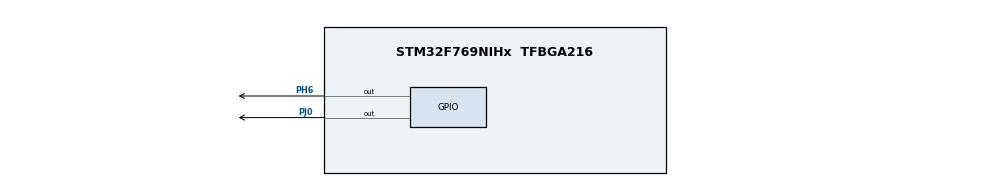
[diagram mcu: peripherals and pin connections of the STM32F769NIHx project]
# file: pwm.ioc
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Mcu.Family=STM32F7
Mcu.Name=STM32F769NIHx
Mcu.Package=TFBGA216
NVIC.PriorityGroup=NVIC_PRIORITYGROUP_4
PH6.Signal=GPIO_Output
PJ0.Signal=GPIO_Output
ProjectManager.HeapSize=0x200
ProjectManager.StackSize=0x400
ProjectManager.TargetToolchain=STM32CubeIDE
RCC.HSE_VALUE=25000000
RCC.HSI_VALUE=16000000
RCC.LSE_VALUE=32768
RCC.USBFreq_Value=96000000
RCC.VCOOutputFreq_Value=192000000
TIM3.Period=499
TIM3.Prescaler=48000
VP_TIM3_VS_ClockSourceINT.Mode=Internal
board=custom

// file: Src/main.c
/* USER CODE BEGIN Header */
/**
  ******************************************************************************
  * @file           : main.c
  * @brief          : Main program body
  ******************************************************************************
  * @attention
  *
  * <h2><center>&copy; Copyright (c) 2019 STMicroelectronics.
  * All rights reserved.</center></h2>
  *
  * This software component is licensed by ST under BSD 3-Clause license,
  * the "License"; You may not use this file except in compliance with the
  * License. You may obtain a copy of the License at:
  *                        opensource.org/licenses/BSD-3-Clause
  *
  ******************************************************************************
  */
/* USER CODE END Header */

#include "main.h"

TIM_HandleTypeDef htim3;

void SystemClock_Config(void);
static void MX_GPIO_Init(void);
static void MX_TIM3_Init(void);

/* USER CODE BEGIN 0 */

/*void HAL_TIM_PeriodElapsedCallback(TIM_HandleTypeDef *htim){
	if(htim->Instance==TIM3){
		HAL_GPIO_TogglePin(GPIOH,GPIO_PIN_6);
	}
}*/

void TIM3_IRQHandler(void){
	/*if(TIM3->SR & TIM_SR_UIF){ //2000
	  TIM3->SR &= ~TIM_SR_UIF;
	  HAL_GPIO_WritePin(GPIOJ,GPIO_PIN_0,GPIO_PIN_RESET);
	}
	else if(TIM3->SR & TIM_SR_CC3OF){ //1000
		TIM3->SR &= ~TIM_SR_CC3OF;
		HAL_GPIO_WritePin(GPIOJ,GPIO_PIN_0,GPIO_PIN_SET);
	}*/
	if(TIM3->SR & TIM_SR_UIF) // if UIF flag is set
	  {
	  TIM3->SR &= ~TIM_SR_UIF;  // clear UIF flag
	  TIM3->CCR3 += 5;	         // increase ch3 duty
	  if(TIM3->CCR3 == 100)	{    // if maximum
	    TIM3->CCR3 = 0;	        // set to zero
	    HAL_GPIO_WritePin(GPIOJ,GPIO_PIN_0,GPIO_PIN_RESET);
	  }
	  TIM3->CCR4 -= 5;	         // decrease ch4 duty
	  if(TIM3->CCR4 == 0)	      // if minimum
	  {
	    TIM3->CCR4 = 250;	      // set to maximum
	    HAL_GPIO_WritePin(GPIOJ,GPIO_PIN_0,GPIO_PIN_SET);
	  }
	}
}

/* USER CODE END 0 */

int main(void)
{

  /* MCU Configuration--------------------------------------------------------*/

  /* Reset of all peripherals, Initializes the Flash interface and the Systick. */
  HAL_Init();

  /* Configure the system clock */
  SystemClock_Config();

  /* Initialize all configured peripherals */
  MX_GPIO_Init();
  MX_TIM3_Init();
  /* USER CODE BEGIN 2 */
  //HAL_TIM_Base_Start_IT(&htim3);
/* RCC->APB1ENR |= RCC_APB1ENR_TIM3EN;
  TIM3->PSC  = 15999;
  TIM3->ARR = 2000;
  TIM3->CCER = 256;
  TIM3->CR1  = TIM_CR1_CEN;
  TIM3->CCMR2 = TIM_CCMR2_OC3M_2 | TIM_CCMR2_OC3M_1; // PWM mode on channel 3

  TIM3->CCR3 = 1000;

  TIM3->DIER = TIM_DIER_UIE | TIM_DIER_CC3IE; // Enable update interrupt (timer level)
  NVIC_EnableIRQ(TIM3_IRQn); // Enable interrupt from TIM3 (NVIC level)
  */
  TIM3->PSC = 0;	// Set prescaler to 24 000 (PSC + 1)
  TIM3->ARR = 250;	// Auto reload value 500

  TIM3->CCR3 = 0;	  // Start PWM duty for channel 3
  TIM3->CCR4 = 500; // Start PWM duty for channel 4

  TIM3->CCMR2 = TIM_CCMR2_OC4M_2 | TIM_CCMR2_OC4M_1 |
                TIM_CCMR2_OC3M_2 | TIM_CCMR2_OC3M_1; // PWM mode on channel 3 & 4

  TIM3->CCER = TIM_CCER_CC4E | TIM_CCER_CC3E; // Enable compare on channel 3 & 4
  TIM3->CR1  = TIM_CR1_CEN;	// Enable timer

  TIM3->DIER = TIM_DIER_UIE; // Enable update interrupt (timer level)
  NVIC_EnableIRQ(TIM3_IRQn); // Enable interrupt from TIM3 (NVIC level)

  /* USER CODE END 2 */

  /* Infinite loop */
  while (1)
  {
	  HAL_GPIO_WritePin(GPIOH,GPIO_PIN_6,GPIO_PIN_SET);
	  HAL_Delay(1000);
	  HAL_GPIO_WritePin(GPIOH,GPIO_PIN_6,GPIO_PIN_RESET);
	  HAL_Delay(1000);

  }
}

void SystemClock_Config(void)
{
  RCC_OscInitTypeDef RCC_OscInitStruct = {0};
  RCC_ClkInitTypeDef RCC_ClkInitStruct = {0};

  /** Configure the main internal regulator output voltage
  */
  __HAL_RCC_PWR_CLK_ENABLE();
  __HAL_PWR_VOLTAGESCALING_CONFIG(PWR_REGULATOR_VOLTAGE_SCALE3);
  /** Initializes the CPU, AHB and APB busses clocks
  */
  RCC_OscInitStruct.OscillatorType = RCC_OSCILLATORTYPE_HSI;
  RCC_OscInitStruct.HSIState = RCC_HSI_ON;
  RCC_OscInitStruct.HSICalibrationValue = RCC_HSICALIBRATION_DEFAULT;
  RCC_OscInitStruct.PLL.PLLState = RCC_PLL_NONE;
  if (HAL_RCC_OscConfig(&RCC_OscInitStruct) != HAL_OK)
  {
    Error_Handler();
  }
  /** Initializes the CPU, AHB and APB busses clocks
  */
  RCC_ClkInitStruct.ClockType = RCC_CLOCKTYPE_HCLK|RCC_CLOCKTYPE_SYSCLK
                              |RCC_CLOCKTYPE_PCLK1|RCC_CLOCKTYPE_PCLK2;
  RCC_ClkInitStruct.SYSCLKSource = RCC_SYSCLKSOURCE_HSI;
  RCC_ClkInitStruct.AHBCLKDivider = RCC_SYSCLK_DIV1;
  RCC_ClkInitStruct.APB1CLKDivider = RCC_HCLK_DIV1;
  RCC_ClkInitStruct.APB2CLKDivider = RCC_HCLK_DIV1;

  if (HAL_RCC_ClockConfig(&RCC_ClkInitStruct, FLASH_LATENCY_0) != HAL_OK)
  {
    Error_Handler();
  }
}

static void MX_TIM3_Init(void)
{

  TIM_ClockConfigTypeDef sClockSourceConfig = {0};
  TIM_MasterConfigTypeDef sMasterConfig = {0};

  htim3.Instance = TIM3;
  htim3.Init.Prescaler = 48000;
  htim3.Init.CounterMode = TIM_COUNTERMODE_UP;
  htim3.Init.Period = 499;
  htim3.Init.ClockDivision = TIM_CLOCKDIVISION_DIV1;
  htim3.Init.AutoReloadPreload = TIM_AUTORELOAD_PRELOAD_DISABLE;
  if (HAL_TIM_Base_Init(&htim3) != HAL_OK)
  {
    Error_Handler();
  }
  sClockSourceConfig.ClockSource = TIM_CLOCKSOURCE_INTERNAL;
  if (HAL_TIM_ConfigClockSource(&htim3, &sClockSourceConfig) != HAL_OK)
  {
    Error_Handler();
  }
  sMasterConfig.MasterOutputTrigger = TIM_TRGO_RESET;
  sMasterConfig.MasterSlaveMode = TIM_MASTERSLAVEMODE_DISABLE;
  if (HAL_TIMEx_MasterConfigSynchronization(&htim3, &sMasterConfig) != HAL_OK)
  {
    Error_Handler();
  }

}

static void MX_GPIO_Init(void)
{
  GPIO_InitTypeDef GPIO_InitStruct = {0};

  /* GPIO Ports Clock Enable */
  __HAL_RCC_GPIOH_CLK_ENABLE();
  __HAL_RCC_GPIOJ_CLK_ENABLE();

  /*Configure GPIO pin Output Level */
  HAL_GPIO_WritePin(GPIOH, GPIO_PIN_6, GPIO_PIN_RESET);

  /*Configure GPIO pin Output Level */
  HAL_GPIO_WritePin(GPIOJ, GPIO_PIN_0, GPIO_PIN_RESET);

  /*Configure GPIO pin : PH6 */
  GPIO_InitStruct.Pin = GPIO_PIN_6;
  GPIO_InitStruct.Mode = GPIO_MODE_OUTPUT_PP;
  GPIO_InitStruct.Pull = GPIO_NOPULL;
  GPIO_InitStruct.Speed = GPIO_SPEED_FREQ_LOW;
  HAL_GPIO_Init(GPIOH, &GPIO_InitStruct);

  /*Configure GPIO pin : PJ0 */
  GPIO_InitStruct.Pin = GPIO_PIN_0;
  GPIO_InitStruct.Mode = GPIO_MODE_OUTPUT_PP;
  GPIO_InitStruct.Pull = GPIO_NOPULL;
  GPIO_InitStruct.Speed = GPIO_SPEED_FREQ_LOW;
  HAL_GPIO_Init(GPIOJ, &GPIO_InitStruct);

}

void Error_Handler(void)
{
}

/************************ (C) COPYRIGHT STMicroelectronics *****END OF FILE****/
